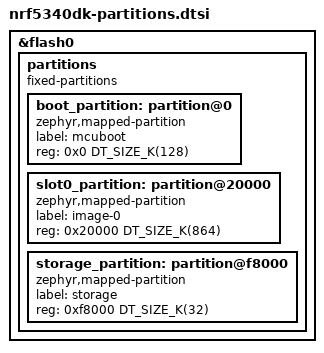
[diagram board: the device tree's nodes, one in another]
/* Partition layout for nrf5340dk: the flash memory map shared by the
 * bootloader and every application image. Generated by
 * tools/partition_layout.py; do not edit by hand -- re-run
 * `python3 tools/partition_layout.py --fix nrf5340dk` after changing
 * the upstream board geometry or tools/boards.toml.
 *
 * Board-specific overlay glue (delete-nodes, device enablement,
 * aliases/chosen) lives in dts/nordic/nrf5340dk.dtsi, which includes
 * this file.
 */

&flash0 {
	partitions {
		compatible = "fixed-partitions";
		#address-cells = <1>;
		#size-cells = <1>;
		ranges;

		boot_partition: partition@0 {
			compatible = "zephyr,mapped-partition";
			label = "mcuboot";
			reg = <0x0 DT_SIZE_K(128)>;
		};

		slot0_partition: partition@20000 {
			compatible = "zephyr,mapped-partition";
			label = "image-0";
			reg = <0x20000 DT_SIZE_K(864)>;
		};

		storage_partition: partition@f8000 {
			compatible = "zephyr,mapped-partition";
			label = "storage";
			reg = <0xf8000 DT_SIZE_K(32)>;
		};
	};
};
